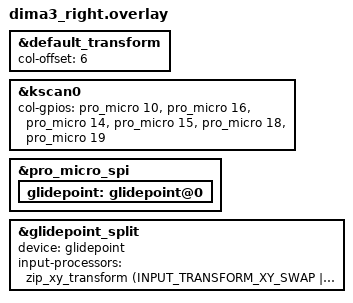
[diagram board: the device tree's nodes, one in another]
/*
 * Copyright (c) 2020 Pete Johanson
 *
 * SPDX-License-Identifier: MIT
 */

#include "dima3.dtsi"

&default_transform {
    col-offset = <6>;
};

&kscan0 {
    col-gpios
        = <&pro_micro 10 GPIO_ACTIVE_HIGH>
        , <&pro_micro 16 GPIO_ACTIVE_HIGH>
        , <&pro_micro 14 GPIO_ACTIVE_HIGH>
        , <&pro_micro 15 GPIO_ACTIVE_HIGH>
        , <&pro_micro 18 GPIO_ACTIVE_HIGH>
        , <&pro_micro 19 GPIO_ACTIVE_HIGH>
        ;
};


// Node from the previous Input Device section
&pro_micro_spi {
    /* ... */

    glidepoint: glidepoint@0 {
        /* ... */
    };
};

// Overrides for the input-split child node
&glidepoint_split {
    device = <&glidepoint>;

    // Optional
    input-processors = <&zip_xy_transform (INPUT_TRANSFORM_XY_SWAP | INPUT_TRANSFORM_X_INVERT | INPUT_TRANSFORM_Y_INVERT)>;
};
